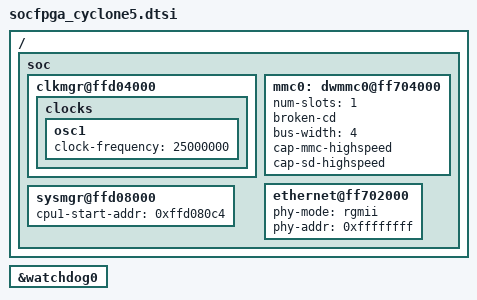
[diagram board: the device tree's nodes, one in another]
/*
 * Copyright Altera Corporation (C) 2012,2014. All rights reserved.
 *
 * This program is free software; you can redistribute it and/or modify
 * it under the terms and conditions of the GNU General Public License,
 * version 2, as published by the Free Software Foundation.
 *
 * This program is distributed in the hope it will be useful, but WITHOUT
 * ANY WARRANTY; without even the implied warranty of MERCHANTABILITY or
 * FITNESS FOR A PARTICULAR PURPOSE.  See the GNU General Public License for
 * more details.
 *
 * You should have received a copy of the GNU General Public License along with
 * this program.  If not, see <http://www.gnu.org/licenses/>.
 */

/dts-v1/;
/* First 4KB has trampoline code for secondary cores. */
/memreserve/ 0x00000000 0x0001000;
#include "socfpga.dtsi"

/ {
	soc {
		clkmgr@ffd04000 {
			clocks {
				osc1 {
					clock-frequency = <25000000>;
				};
			};
		};

		mmc0: dwmmc0@ff704000 {
			num-slots = <1>;
			broken-cd;
			bus-width = <4>;
			cap-mmc-highspeed;
			cap-sd-highspeed;
		};

		ethernet@ff702000 {
			phy-mode = "rgmii";
			phy-addr = <0xffffffff>; /* probe for phy addr */
			status = "okay";
		};

		sysmgr@ffd08000 {
			cpu1-start-addr = <0xffd080c4>;
		};
		/*
		hps_0_bridges_h2f_lw: bridge@0xff200000 {
		reg = < 0xFF200000 0x00200000 >;
		#address-cells = < 1 >;
		#size-cells = < 1 >;
		compatible = "simple-bus";	
		
		ranges = < 	
				0x00000020 0xFF200020 0x00000020                             //i2c master	
				0x00000100 0xFF200100 0x00000080                            //frame reader	
				0x00000200 0xFF200200 0x00000010                             //irq pen
			>;

			alt_vip_vfr_1: vip@0x100 {
				compatible = "ALTR,vip-frame-reader-13.0", "ALTR,vip-frame-reader-9.1";
				reg = < 0x00000100 0x00000080 >;
				max-width = < 800 >;	 
				max-height = < 480 >;	 
				mem-word-width = < 256 >;
				bits-per-color = < 8 >;

			}; //end vip@0x40100 (alt_vip_vfr_0)
			
			i2c_ocre: ocores@0x20 {
				#address-cells = <1>;
				#size-cells = <0>;
				compatible = "opencores,i2c-ocores";
				reg = <0x00000020 0x20>;
				interrupts = <0 42 1>;
				clock-frequency = <50000000>;
				reg-shift = <2>;
				reg-io-width = <4>;
				ft5406_ts@0x38 {
					compatible = "ft5406_ts";	
					reg = < 0x38 >;	
					interrupts = <0 40 3>;
					//interrupts = < 0 >;	
					//interrupt-parent = < &touch_panel_pen_irq_n >;	
				}; //end ts@0 (ts0)
			 }; 
		}; //end bridge@0xff200000 (hps_0_bridges_h2f_lw)
		*/
	};
};

&watchdog0 {
	status = "okay";
};
